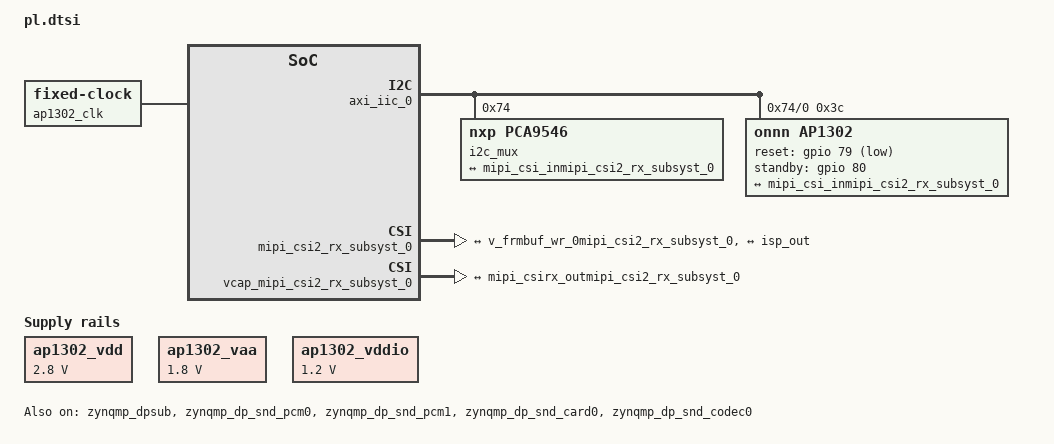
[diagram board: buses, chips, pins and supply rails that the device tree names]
/*
 * CAUTION: This file is automatically generated by Xilinx.
 * Version:  
 * Today is: Wed May 27 06:41:20 2026
 */


/dts-v1/;
/plugin/;
/ {
	fragment@0 {
		target = <&fpga_full>;
		overlay0: __overlay__ {
			#address-cells = <2>;
			#size-cells = <2>;
			firmware-name = "design_1_wrapper.bit.bin";
			resets = <&zynqmp_reset 116>;
		};
	};
	fragment@1 {
		target = <&amba>;
		overlay1: __overlay__ {
			afi0: afi0 {
				compatible = "xlnx,afi-fpga";
				config-afi = < 0 0>, <1 0>, <2 0>, <3 0>, <4 0>, <5 0>, <6 0>, <7 0>, <8 0>, <9 0>, <10 0>, <11 0>, <12 0>, <13 0>, <14 0xa00>, <15 0x000>;
			};
			clocking0: clocking0 {
				#clock-cells = <0>;
				assigned-clock-rates = <99999001>;
				assigned-clocks = <&zynqmp_clk 71>;
				clock-output-names = "fabric_clk";
				clocks = <&zynqmp_clk 71>;
				compatible = "xlnx,fclk";
			};
			clocking1: clocking1 {
				#clock-cells = <0>;
				assigned-clock-rates = <99999001>;
				assigned-clocks = <&zynqmp_clk 72>;
				clock-output-names = "fabric_clk";
				clocks = <&zynqmp_clk 72>;
				compatible = "xlnx,fclk";
			};
		};
	};
	fragment@2 {
		target = <&amba>;
		overlay2: __overlay__ {
			#address-cells = <2>;
			#size-cells = <2>;
                        ap1302_clk: sensor_clk {
                                #clock-cells = <0x0>;
                                compatible = "fixed-clock";
                                clock-frequency = <0x48000000>;
                        };
                        ap1302_vdd: fixedregulator@0 {
                                compatible = "regulator-fixed";
                                regulator-name = "ap1302_vdd";
                                regulator-min-microvolt = <2800000>;
                                regulator-max-microvolt = <2800000>;
                                enable-active-high;
                        };

                        ap1302_vaa: fixedregulator@1 {
                                compatible = "regulator-fixed";
                                regulator-name = "ap1302_vaa";
                                regulator-min-microvolt = <1800000>;
                                regulator-max-microvolt = <1800000>;
                        };

                        ap1302_vddio: fixedregulator@2 {
                                compatible = "regulator-fixed";
                                regulator-name = "ap1302_vddio";
                                regulator-min-microvolt = <1200000>;
                                regulator-max-microvolt = <1200000>;
                        };
			axi_iic_0: i2c@a0020000 {
				#address-cells = <1>;
				#size-cells = <0>;
				clock-names = "s_axi_aclk";
				clocks = <&zynqmp_clk 71>;
				compatible = "xlnx,axi-iic-2.1", "xlnx,xps-iic-2.00.a";
				interrupt-names = "iic2intc_irpt";
				interrupt-parent = <&gic>;
				interrupts = <0 91 4>;
				reg = <0x0 0xa0020000 0x0 0x10000>;

				i2c_mux: i2c-mux@74 {
					compatible = "nxp,pca9546";
					#address-cells = <1>;
					#size-cells = <0>;
					reg = <0x74>;
					i2c@0 {
						#address-cells = <1>;
						#size-cells = <0>;
						reg = <0>;
						ap1302: isp@3c {
							compatible = "onnn,ap1302";
							reg = <0x3c>;
							#address-cells = <1>;
							#size-cells = <0>;
							reset-gpios = <&gpio 79 1>;
							standby-gpios = <&gpio 80 0>;
							clocks = <&ap1302_clk>;
							sensors {
								#address-cells = <1>;
								#size-cells = <0>;
								onnn,model = "onnn,ar1335";
								sensor@0 {
									reg = <0>;
									vdd-supply = <&ap1302_vdd>;
									vaa-supply = <&ap1302_vaa>;
									vddio-supply = <&ap1302_vddio>;
								};
							};
							ports {
								#address-cells = <1>;
								#size-cells = <0>;
								port@0 {
									reg = <2>;
									isp_out: endpoint {
										remote-endpoint = <&mipi_csi_inmipi_csi2_rx_subsyst_0>;
										data-lanes = <1 2 3 4>;
									};
								};
							};
						};
					};
				};
			};
			mipi_csi2_rx_subsyst_0: mipi_csi2_rx_subsystem@a0000000 {
				clock-names = "lite_aclk", "dphy_clk_200M", "video_aclk";
				clocks = <&zynqmp_clk 71>, <&misc_clk_0>, <&misc_clk_1>;
				compatible = "xlnx,mipi-csi2-rx-subsystem-5.1", "xlnx,mipi-csi2-rx-subsystem-5.0";
				interrupt-names = "csirxss_csi_irq";
				interrupt-parent = <&gic>;
				interrupts = <0 89 4>;
				reg = <0x0 0xa0000000 0x0 0x1000>;
				xlnx,csi-pxl-format = <0x18>;
				xlnx,axis-tdata-width = <32>;
				xlnx,max-lanes = <4>;
				xlnx,en-active-lanes;
				xlnx,ppc = <2>;
				xlnx,vc = <4>;
				xlnx,vfb ;
				mipi_csi_portsmipi_csi2_rx_subsyst_0: ports {
					#address-cells = <1>;
					#size-cells = <0>;
					mipi_csi_port1mipi_csi2_rx_subsyst_0: port@1 {
						/* Fill cfa-pattern=rggb for raw data types, other fields video-format and video-width user needs to fill */
						reg = <1>;						
						mipi_csirx_outmipi_csi2_rx_subsyst_0: endpoint {
							remote-endpoint = <&v_frmbuf_wr_0mipi_csi2_rx_subsyst_0>;
						};
					};
					mipi_csi_port0mipi_csi2_rx_subsyst_0: port@0 {
						/* Fill cfa-pattern=rggb for raw data types, other fields video-format,video-width user needs to fill */
						/* User need to add something like remote-endpoint=<&out> under the node csiss_in:endpoint */
						reg = <0>;						
						mipi_csi_inmipi_csi2_rx_subsyst_0: endpoint {
							data-lanes = <1 2 3 4>;
							remote-endpoint = <&isp_out>;
						};
					};
				};
			};
			misc_clk_0: misc_clk_0 {
				#clock-cells = <0>;
				clock-frequency = <199998000>;
				compatible = "fixed-clock";
			};
			misc_clk_1: misc_clk_1 {
				#clock-cells = <0>;
				clock-frequency = <249997500>;
				compatible = "fixed-clock";
			};
			v_frmbuf_wr_0: v_frmbuf_wr@a0010000 {
				#dma-cells = <1>;
				clock-names = "ap_clk";
				clocks = <&misc_clk_1>;
				compatible = "xlnx,v-frmbuf-wr-2.3", "xlnx,axi-frmbuf-wr-v2.2";
				interrupt-names = "interrupt";
				interrupt-parent = <&gic>;
				interrupts = <0 90 4>;
				reg = <0x0 0xa0010000 0x0 0x10000>;
				reset-gpios = <&gpio 78 1>;
				xlnx,dma-addr-width = <32>;
				xlnx,dma-align = <16>;
				xlnx,max-height = <2160>;
				xlnx,max-width = <3840>;
				xlnx,pixels-per-clock = <2>;
				xlnx,s-axi-ctrl-addr-width = <0x7>;
				xlnx,s-axi-ctrl-data-width = <0x20>;
				xlnx,vid-formats = "bgr888", "uyvy", "yuyv", "nv12", "nv16";
				xlnx,video-width = <8>;
			};
			vcap_mipi_csi2_rx_subsyst_0 {
				compatible = "xlnx,video";
				dma-names = "port0";
				dmas = <&v_frmbuf_wr_0 0>;
				vcap_portsmipi_csi2_rx_subsyst_0: ports {
					#address-cells = <1>;
					#size-cells = <0>;
					vcap_portmipi_csi2_rx_subsyst_0: port@0 {
						direction = "input";
						reg = <0>;
						v_frmbuf_wr_0mipi_csi2_rx_subsyst_0: endpoint {
							remote-endpoint = <&mipi_csirx_outmipi_csi2_rx_subsyst_0>;
						};
					};
				};
			};
		};
	};
	fragment@3 {
		target = <&zynqmp_dpsub>;
		__overlay__ {
			status = "okay";
		};
	};

	fragment@4 {
		target = <&zynqmp_dp_snd_pcm0>;
		__overlay__ {
			status = "okay";
		};
	};

	fragment@5 {
		target = <&zynqmp_dp_snd_pcm1>;
		__overlay__ {
			status = "okay";
		};
	};

	fragment@6 {
		target = <&zynqmp_dp_snd_card0>;
		__overlay__ {
			status = "okay";
		};
	};

	fragment@7 {
		target = <&zynqmp_dp_snd_codec0>;
		__overlay__ {
			status = "okay";
		};
	};
};


